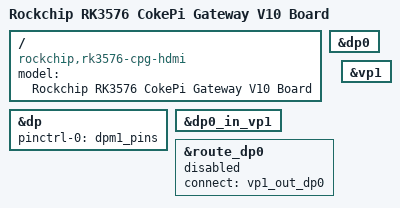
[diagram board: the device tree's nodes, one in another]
// SPDX-License-Identifier: (GPL-2.0+ OR MIT)
/*
 * Copyright (c) 2024 Rockchip Electronics Co., Ltd.
 *
 */

/dts-v1/;

#include "rk3576.dtsi"
#include "rk3576-cokepi-lite.dtsi"
#include "rk3576-cokepi-cameras.dtsi"
#include "rk3576-linux.dtsi"

/ {
	model = "Rockchip RK3576 CokePi Gateway V10 Board";
	compatible = "rockchip,rk3576-cpg-hdmi", "rockchip,rk3576";
};

&dp {
	pinctrl-0 = <&dpm1_pins>;
	pinctrl-names = "default";
	status = "okay";
};

&dp0 {
	status = "okay";
};

&dp0_in_vp1 {
	status = "okay";
};

&route_dp0 {
	status = "disabled";
	connect = <&vp1_out_dp0>;
};

&vp1 {
	status = "okay";
};
